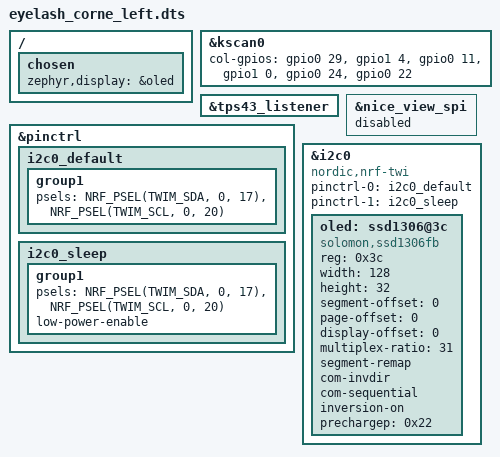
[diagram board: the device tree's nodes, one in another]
/*
*
* Copyright (c) 2024 The ZMK Contributors
* SPDX-License-Identifier: MIT
*
*/

#include "eyelash_corne.dtsi"

/* Key-matrix columns (LEFT half) -- rolio sofle's 6 cols, translated pro_micro -> nRF.
 * Both halves share these 6 cols; the RIGHT half shifts them with col-offset = 6. */
&kscan0 {
    col-gpios
        = <&gpio0 29 GPIO_ACTIVE_HIGH>   /* pro_micro 20 -> P0.29 */
        , <&gpio1 4  GPIO_ACTIVE_HIGH>   /* pro_micro 8  -> P1.04 */
        , <&gpio0 11 GPIO_ACTIVE_HIGH>   /* pro_micro 7  -> P0.11 */
        , <&gpio1 0  GPIO_ACTIVE_HIGH>   /* pro_micro 6  -> P1.00 */
        , <&gpio0 24 GPIO_ACTIVE_HIGH>   /* pro_micro 5  -> P0.24 */
        , <&gpio0 22 GPIO_ACTIVE_HIGH>   /* pro_micro 4  -> P0.22 */
        ;
};

/* No rotary encoder on this hardware (plain Corne) -- left_encoder stays disabled. */

/* LEFT = central: turn the touchpad listener on so relayed events become HID. */
&tps43_listener {
    status = "okay";
};

/*
 * SSD1306 OLED (128x32) on I2C0 @0x3c -- the panel this hardware actually has
 * (mirrors the rolio sofle OLED). P0.17/P0.20 are shared: SPI0 (the board's
 * nice_view_spi) and I2C0 are the SAME nRF instance (0x40003000), and the RIGHT half
 * uses these same I2C0 pins for the touchpad. Here on the LEFT we free SPI0 and let
 * I2C0 drive the display.
 */
&nice_view_spi {
    status = "disabled";
};

&pinctrl {
    i2c0_default: i2c0_default {
        group1 {
            psels = <NRF_PSEL(TWIM_SDA, 0, 17)>,
                    <NRF_PSEL(TWIM_SCL, 0, 20)>;
        };
    };
    i2c0_sleep: i2c0_sleep {
        group1 {
            psels = <NRF_PSEL(TWIM_SDA, 0, 17)>,
                    <NRF_PSEL(TWIM_SCL, 0, 20)>;
            low-power-enable;
        };
    };
};

&i2c0 {
    /*
     * Use the legacy TWI (nordic,nrf-twi), NOT TWIM (EasyDMA), to match rolio
     * EXACTLY. rolio's &pro_micro_i2c resolves to nordic,nrf-twi; forcing TWIM here
     * broke the display: TWIM's EasyDMA cannot transmit from flash/RODATA buffers,
     * so the SSD1306's const init/command sequences silently fail and the panel
     * stays OFF. The legacy TWI driver clocks bytes out from any memory, so it
     * works. (Same fix applies to the touchpad on the right half.)
     */
    compatible = "nordic,nrf-twi";
    status = "okay";
    pinctrl-0 = <&i2c0_default>;
    pinctrl-1 = <&i2c0_sleep>;
    pinctrl-names = "default", "sleep";

    oled: ssd1306@3c {
        compatible = "solomon,ssd1306fb";
        reg = <0x3c>;
        width = <128>;
        height = <32>;
        segment-offset = <0>;
        page-offset = <0>;
        display-offset = <0>;
        multiplex-ratio = <31>;
        segment-remap;
        com-invdir;
        com-sequential;
        inversion-on;
        prechargep = <0x22>;
    };
};

/ {
    chosen {
        zephyr,display = &oled;
    };
};
